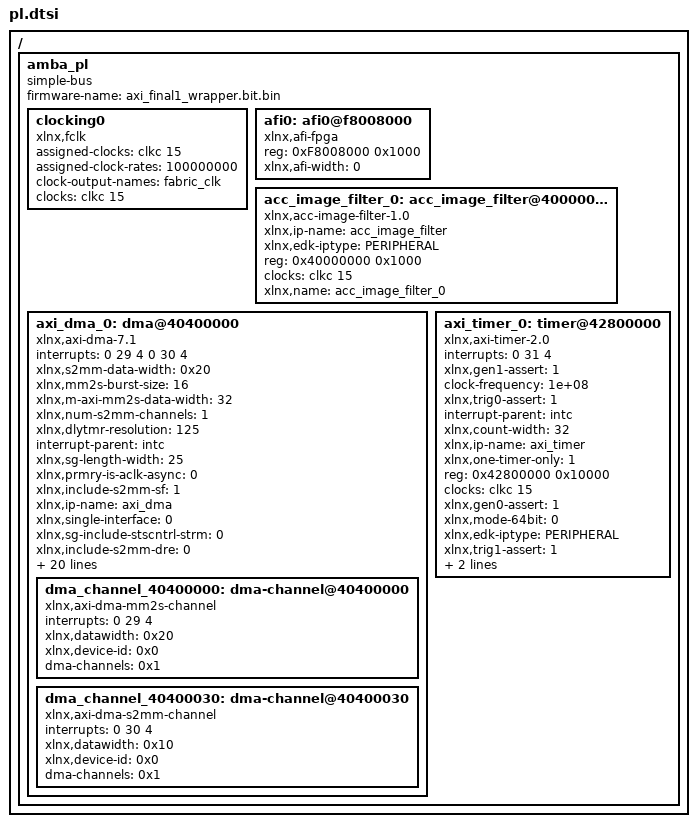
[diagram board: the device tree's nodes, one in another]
/ {
	amba_pl: amba_pl {
		ranges;
		compatible = "simple-bus";
		#address-cells = <1>;
		#size-cells = <1>;
		firmware-name = "axi_final1_wrapper.bit.bin";
		clocking0: clocking0 {
			compatible = "xlnx,fclk";
			assigned-clocks = <&clkc 15>;
			assigned-clock-rates = <100000000>;
			#clock-cells = <0>;
			clock-output-names = "fabric_clk";
			clocks = <&clkc 15>;
		};
		afi0: afi0@f8008000 {
			status = "okay";
			compatible = "xlnx,afi-fpga";
			#address-cells = <1>;
			reg = <0xF8008000 0x1000>;
			#size-cells = <0>;
			xlnx,afi-width = <0>;
		};
		acc_image_filter_0: acc_image_filter@40000000 {
			compatible = "xlnx,acc-image-filter-1.0";
			status = "okay";
			clock-names = "clk";
			xlnx,ip-name = "acc_image_filter";
			xlnx,edk-iptype = "PERIPHERAL";
			reg = <0x40000000 0x1000>;
			clocks = <&clkc 15>;
			xlnx,name = "acc_image_filter_0";
		};
		axi_dma_0: dma@40400000 {
			interrupts = < 0 29 4 0 30 4 >;
			compatible = "xlnx,axi-dma-7.1" , "xlnx,axi-dma-1.00.a";
			xlnx,s2mm-data-width = <0x20>;
			xlnx,mm2s-burst-size = <16>;
			xlnx,m-axi-mm2s-data-width = <32>;
			xlnx,num-s2mm-channels = <1>;
			xlnx,dlytmr-resolution = <125>;
			interrupt-parent = <&intc>;
			xlnx,sg-length-width = <25>;
			xlnx,prmry-is-aclk-async = <0>;
			xlnx,include-s2mm-sf = <1>;
			#dma-cells = <1>;
			xlnx,ip-name = "axi_dma";
			xlnx,single-interface = <0>;
			xlnx,sg-include-stscntrl-strm = <0>;
			xlnx,include-s2mm-dre = <0>;
			reg = <0x40400000 0x10000>;
			xlnx,addr-width = <32>;
			xlnx,include-s2mm = <1>;
			clocks = <&clkc 15>, <&clkc 15>, <&clkc 15>;
			xlnx,s-axis-s2mm-tdata-width = <16>;
			xlnx,micro-dma = <0>;
			xlnx,increase-throughput = <0>;
			xlnx,mm2s-data-width = <0x20>;
			xlnx,addrwidth = <0x20>;
			xlnx,sg-use-stsapp-length = <0>;
			xlnx,m-axis-mm2s-tdata-width = <8>;
			xlnx,edk-iptype = "PERIPHERAL";
			xlnx,s2mm-burst-size = <16>;
			xlnx,m-axi-s2mm-data-width = <32>;
			xlnx,num-mm2s-channels = <1>;
			xlnx,enable-multi-channel = <0>;
			status = "okay";
			xlnx,include-mm2s-sf = <1>;
			clock-names = "m_axi_mm2s_aclk" , "m_axi_s2mm_aclk" , "s_axi_lite_aclk";
			interrupt-names = "mm2s_introut" , "s2mm_introut";
			xlnx,include-mm2s = <1>;
			xlnx,include-mm2s-dre = <0>;
			xlnx,name = "axi_dma_0";
			dma_channel_40400000: dma-channel@40400000 {
				interrupts = <0 29 4>;
				xlnx,datawidth = <0x20>;
				xlnx,device-id = <0x0>;
				compatible = "xlnx,axi-dma-mm2s-channel";
				dma-channels = <0x1>;
			};
			dma_channel_40400030: dma-channel@40400030 {
				interrupts = <0 30 4>;
				xlnx,datawidth = <0x10>;
				xlnx,device-id = <0x0>;
				compatible = "xlnx,axi-dma-s2mm-channel";
				dma-channels = <0x1>;
			};
		};
		axi_timer_0: timer@42800000 {
			interrupts = < 0 31 4 >;
			compatible = "xlnx,axi-timer-2.0" , "xlnx,xps-timer-1.00.a";
			xlnx,gen1-assert = <1>;
			clock-frequency = "1e+08";
			xlnx,trig0-assert = <1>;
			interrupt-parent = <&intc>;
			xlnx,count-width = <32>;
			xlnx,ip-name = "axi_timer";
			xlnx,one-timer-only = <1>;
			reg = <0x42800000 0x10000>;
			clocks = <&clkc 15>;
			xlnx,gen0-assert = <1>;
			xlnx,mode-64bit = <0>;
			xlnx,edk-iptype = "PERIPHERAL";
			status = "okay";
			xlnx,trig1-assert = <1>;
			clock-names = "s_axi_aclk";
			xlnx,enable-timer2 = <0>;
			interrupt-names = "interrupt";
			xlnx,name = "axi_timer_0";
		};
	};
};
